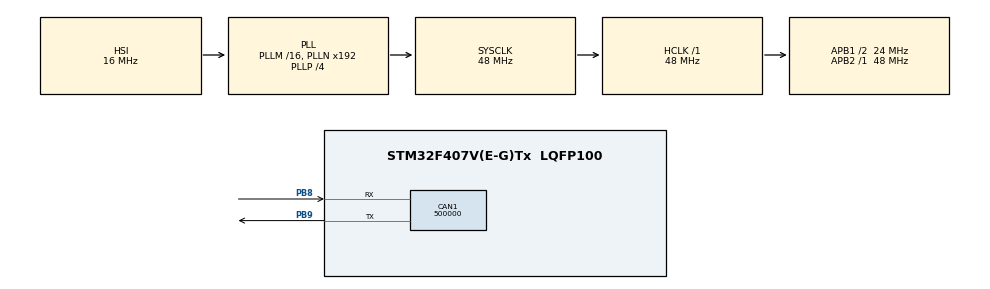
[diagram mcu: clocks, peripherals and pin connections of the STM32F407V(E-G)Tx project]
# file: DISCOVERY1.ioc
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CAN1.CalculateBaudRate=500000
CAN1.CalculateTimeBit=2000
CAN1.CalculateTimeQuantum=666.6666666666666
Mcu.Family=STM32F4
Mcu.Name=STM32F407V(E-G)Tx
Mcu.Package=LQFP100
NVIC.PriorityGroup=NVIC_PRIORITYGROUP_4
NVIC.TIM6_DAC_IRQn=true\:0\:0\:false\:false\:true\:true\:true\:true
PB8.Mode=CAN_Activate
PB8.Signal=CAN1_RX
PB9.Mode=CAN_Activate
PB9.Signal=CAN1_TX
ProjectManager.HeapSize=0x200
ProjectManager.StackSize=0x400
ProjectManager.TargetToolchain=STM32CubeIDE
RCC.AHBFreq_Value=48000000
RCC.APB1CLKDivider=RCC_HCLK_DIV2
RCC.APB1Freq_Value=24000000
RCC.APB1TimFreq_Value=48000000
RCC.APB2Freq_Value=48000000
RCC.APB2TimFreq_Value=48000000
RCC.CortexFreq_Value=48000000
RCC.HCLKFreq_Value=48000000
RCC.HSE_VALUE=25000000
RCC.HSI_VALUE=16000000
RCC.LSE_VALUE=32768
RCC.PLLP=RCC_PLLP_DIV4
RCC.SYSCLKFreq_VALUE=48000000
RCC.SYSCLKSource=RCC_SYSCLKSOURCE_PLLCLK
RCC.VCOOutputFreq_Value=192000000
TIM6.Period=59999
TIM6.Prescaler=399
VP_TIM6_VS_ClockSourceINT.Mode=Enable_Timer
board=custom

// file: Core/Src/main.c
/* USER CODE BEGIN Header */
/**
  ******************************************************************************
  * @file           : main.c
  * @brief          : Main program body
  ******************************************************************************
  * @attention
  *
  * Copyright (c) 2025 STMicroelectronics.
  * All rights reserved.
  *
  * This software is licensed under terms that can be found in the LICENSE file
  * in the root directory of this software component.
  * If no LICENSE file comes with this software, it is provided AS-IS.
  *
  ******************************************************************************
  */
/* USER CODE END Header */
#include "main.h"

CAN_HandleTypeDef hcan1;

TIM_HandleTypeDef htim6;

/* USER CODE BEGIN PV */
volatile uint32_t timetik = 0;
/* USER CODE END PV */

void SystemClock_Config(void);
static void MX_GPIO_Init(void);
static void MX_TIM6_Init(void);
static void MX_CAN1_Init(void);

int main(void)
{

  /* MCU Configuration--------------------------------------------------------*/

  /* Reset of all peripherals, Initializes the Flash interface and the Systick. */
  HAL_Init();

  /* Configure the system clock */
  SystemClock_Config();

  /* Initialize all configured peripherals */
  MX_GPIO_Init();
  MX_TIM6_Init();
  MX_CAN1_Init();
  /* USER CODE BEGIN 2 */
  HAL_TIM_Base_Start_IT(&htim6);
  /* USER CODE END 2 */

  /* Infinite loop */
  while (1)
  {

  }
}

void SystemClock_Config(void)
{
  RCC_OscInitTypeDef RCC_OscInitStruct = {0};
  RCC_ClkInitTypeDef RCC_ClkInitStruct = {0};

  /** Configure the main internal regulator output voltage
  */
  __HAL_RCC_PWR_CLK_ENABLE();
  __HAL_PWR_VOLTAGESCALING_CONFIG(PWR_REGULATOR_VOLTAGE_SCALE1);

  /** Initializes the RCC Oscillators according to the specified parameters
  * in the RCC_OscInitTypeDef structure.
  */
  RCC_OscInitStruct.OscillatorType = RCC_OSCILLATORTYPE_HSI;
  RCC_OscInitStruct.HSIState = RCC_HSI_ON;
  RCC_OscInitStruct.HSICalibrationValue = RCC_HSICALIBRATION_DEFAULT;
  RCC_OscInitStruct.PLL.PLLState = RCC_PLL_ON;
  RCC_OscInitStruct.PLL.PLLSource = RCC_PLLSOURCE_HSI;
  RCC_OscInitStruct.PLL.PLLM = 16;
  RCC_OscInitStruct.PLL.PLLN = 192;
  RCC_OscInitStruct.PLL.PLLP = RCC_PLLP_DIV4;
  RCC_OscInitStruct.PLL.PLLQ = 4;
  if (HAL_RCC_OscConfig(&RCC_OscInitStruct) != HAL_OK)
  {
    Error_Handler();
  }

  /** Initializes the CPU, AHB and APB buses clocks
  */
  RCC_ClkInitStruct.ClockType = RCC_CLOCKTYPE_HCLK|RCC_CLOCKTYPE_SYSCLK
                              |RCC_CLOCKTYPE_PCLK1|RCC_CLOCKTYPE_PCLK2;
  RCC_ClkInitStruct.SYSCLKSource = RCC_SYSCLKSOURCE_PLLCLK;
  RCC_ClkInitStruct.AHBCLKDivider = RCC_SYSCLK_DIV1;
  RCC_ClkInitStruct.APB1CLKDivider = RCC_HCLK_DIV2;
  RCC_ClkInitStruct.APB2CLKDivider = RCC_HCLK_DIV1;

  if (HAL_RCC_ClockConfig(&RCC_ClkInitStruct, FLASH_LATENCY_1) != HAL_OK)
  {
    Error_Handler();
  }
}

static void MX_CAN1_Init(void)
{

  hcan1.Instance = CAN1;
  hcan1.Init.Prescaler = 16;
  hcan1.Init.Mode = CAN_MODE_NORMAL;
  hcan1.Init.SyncJumpWidth = CAN_SJW_1TQ;
  hcan1.Init.TimeSeg1 = CAN_BS1_1TQ;
  hcan1.Init.TimeSeg2 = CAN_BS2_1TQ;
  hcan1.Init.TimeTriggeredMode = DISABLE;
  hcan1.Init.AutoBusOff = DISABLE;
  hcan1.Init.AutoWakeUp = DISABLE;
  hcan1.Init.AutoRetransmission = DISABLE;
  hcan1.Init.ReceiveFifoLocked = DISABLE;
  hcan1.Init.TransmitFifoPriority = DISABLE;
  if (HAL_CAN_Init(&hcan1) != HAL_OK)
  {
    Error_Handler();
  }

}

static void MX_TIM6_Init(void)
{

  TIM_MasterConfigTypeDef sMasterConfig = {0};

  htim6.Instance = TIM6;
  htim6.Init.Prescaler = 399;
  htim6.Init.CounterMode = TIM_COUNTERMODE_UP;
  htim6.Init.Period = 59999;
  htim6.Init.AutoReloadPreload = TIM_AUTORELOAD_PRELOAD_DISABLE;
  if (HAL_TIM_Base_Init(&htim6) != HAL_OK)
  {
    Error_Handler();
  }
  sMasterConfig.MasterOutputTrigger = TIM_TRGO_RESET;
  sMasterConfig.MasterSlaveMode = TIM_MASTERSLAVEMODE_DISABLE;
  if (HAL_TIMEx_MasterConfigSynchronization(&htim6, &sMasterConfig) != HAL_OK)
  {
    Error_Handler();
  }

}

static void MX_GPIO_Init(void)
{

  /* GPIO Ports Clock Enable */
  __HAL_RCC_GPIOB_CLK_ENABLE();

  /* USER CODE BEGIN MX_GPIO_Init_2 */
  __HAL_RCC_GPIOD_CLK_ENABLE();
  GPIO_InitTypeDef gpioled;
  gpioled.Pin = GPIO_PIN_12 | GPIO_PIN_13 | GPIO_PIN_14 | GPIO_PIN_15;
  gpioled.Mode = GPIO_MODE_OUTPUT_PP;
  HAL_GPIO_Init(GPIOD, &gpioled);
  /* USER CODE END MX_GPIO_Init_2 */
}

/* USER CODE BEGIN 4 */
void HAL_TIM_PeriodElapsedCallback(TIM_HandleTypeDef *htim)
{
	if (htim->Instance == TIM6)
	{
		HAL_GPIO_TogglePin(GPIOD, GPIO_PIN_12 | GPIO_PIN_13 | GPIO_PIN_14 | GPIO_PIN_15);
		timetik++;
	}
}
/* USER CODE END 4 */

void Error_Handler(void)
{
  __disable_irq();
  while (1)
  {
  }
}
